# SPC1068 register map
File version: 20180100_70611510
CPU: CM3 r2p1, little endian, MPU, no FPU, 4 interrupt priority bits
Registers are 32-bit, read-write, reset 0x0 unless marked. A register's access mark holds for its fields unless they carry their own. Offsets are from the block's base; [hi:lo] are bit positions.

## PINMUX — Split from GLOBAL
Base 0x4000B000
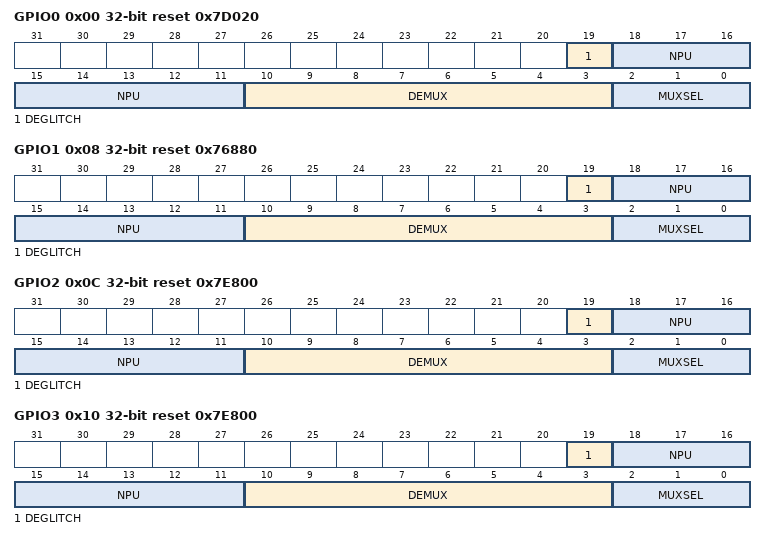
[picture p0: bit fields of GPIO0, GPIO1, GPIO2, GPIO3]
0x00 GPIO0 reset 0x7D020 — GPIO0 Pin Configuration Register
  [19] DEGLITCH — Input de-glitch filtering
    0=DISABLE (Disable de-glitch); 1=ENABLE (Enable de-glitch)
  [18:11] NPU — Disable internal pull-up for each channel
  [10:3] DEMUX — Default value for each demuxed input channel
  [2:0] MUXSEL — Channel select
    0=GPIO0; 1=UART_TXD; 2=I2C_SCL; 7=ECAPO (ECAP output)
0x08 GPIO1 reset 0x76880 — GPIO1 Pin Configuration Register
  [19] DEGLITCH — Input de-glitch filtering
    0=DISABLE (Disable de-glitch); 1=ENABLE (Enable de-glitch)
  [18:11] NPU — Disable internal pull-up for each channel
  [10:3] DEMUX — Default value for each demuxed input channel
  [2:0] MUXSEL — Channel select
    0=ADC0; 1=GPIO1; 2=PWMSYNCI; 3=PWMSYNCO; 4=I2C_SDA; 7=ECAPO (ECAP output)
0x0C GPIO2 reset 0x7E800 — GPIO2 Pin Configuration Register
  [19] DEGLITCH — Input de-glitch filtering
    0=DISABLE (Disable de-glitch); 1=ENABLE (Enable de-glitch)
  [18:11] NPU — Disable internal pull-up for each channel
  [10:3] DEMUX — Default value for each demuxed input channel
  [2:0] MUXSEL — Channel select
    0=ADC1; 1=GPIO2; 2=PWM5B; 7=ECAPO (ECAP output)
0x10 GPIO3 reset 0x7E800 — GPIO3 Pin Configuration Register
  [19] DEGLITCH — Input de-glitch filtering
    0=DISABLE (Disable de-glitch); 1=ENABLE (Enable de-glitch)
  [18:11] NPU — Disable internal pull-up for each channel
  [10:3] DEMUX — Default value for each demuxed input channel
  [2:0] MUXSEL — Channel select
    0=ADC2; 1=GPIO3; 2=PWM5A; 7=ECAPO (ECAP output)
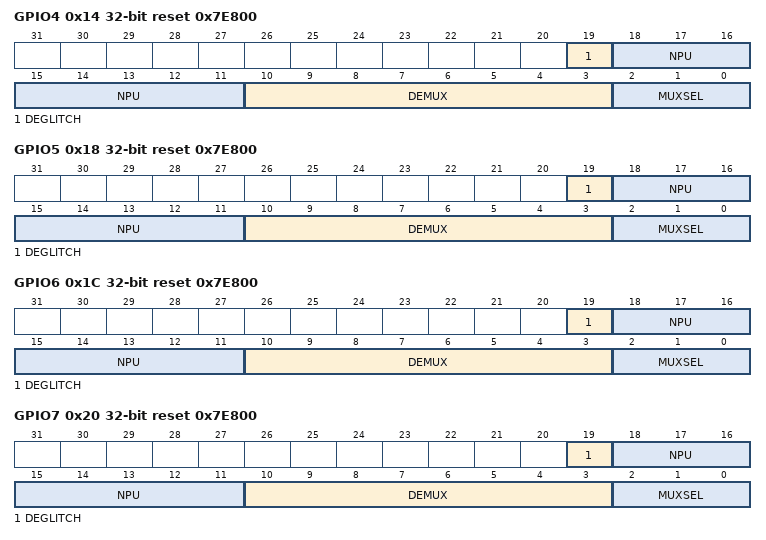
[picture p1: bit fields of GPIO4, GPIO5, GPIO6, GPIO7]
0x14 GPIO4 reset 0x7E800 — GPIO4 Pin Configuration Register
  [19] DEGLITCH — Input de-glitch filtering
    0=DISABLE (Disable de-glitch); 1=ENABLE (Enable de-glitch)
  [18:11] NPU — Disable internal pull-up for each channel
  [10:3] DEMUX — Default value for each demuxed input channel
  [2:0] MUXSEL — Channel select
    0=ADC3; 1=GPIO4; 2=PWM6B; 7=ECAPO (ECAP output)
0x18 GPIO5 reset 0x7E800 — GPIO5 Pin Configuration Register
  [19] DEGLITCH — Input de-glitch filtering
    0=DISABLE (Disable de-glitch); 1=ENABLE (Enable de-glitch)
  [18:11] NPU — Disable internal pull-up for each channel
  [10:3] DEMUX — Default value for each demuxed input channel
  [2:0] MUXSEL — Channel select
    0=ADC4; 1=GPIO5; 2=PWM6A; 7=ECAPO (ECAP output)
0x1C GPIO6 reset 0x7E800 — GPIO6 Pin Configuration Register
  [19] DEGLITCH — Input de-glitch filtering
    0=DISABLE (Disable de-glitch); 1=ENABLE (Enable de-glitch)
  [18:11] NPU — Disable internal pull-up for each channel
  [10:3] DEMUX — Default value for each demuxed input channel
  [2:0] MUXSEL — Channel select
    0=ADC5; 1=GPIO6; 2=PWM4B; 7=ECAPO (ECAP output)
0x20 GPIO7 reset 0x7E800 — GPIO7 Pin Configuration Register
  [19] DEGLITCH — Input de-glitch filtering
    0=DISABLE (Disable de-glitch); 1=ENABLE (Enable de-glitch)
  [18:11] NPU — Disable internal pull-up for each channel
  [10:3] DEMUX — Default value for each demuxed input channel
  [2:0] MUXSEL — Channel select
    0=ADC6; 1=GPIO7; 2=PWM4A; 7=ECAPO (ECAP output)
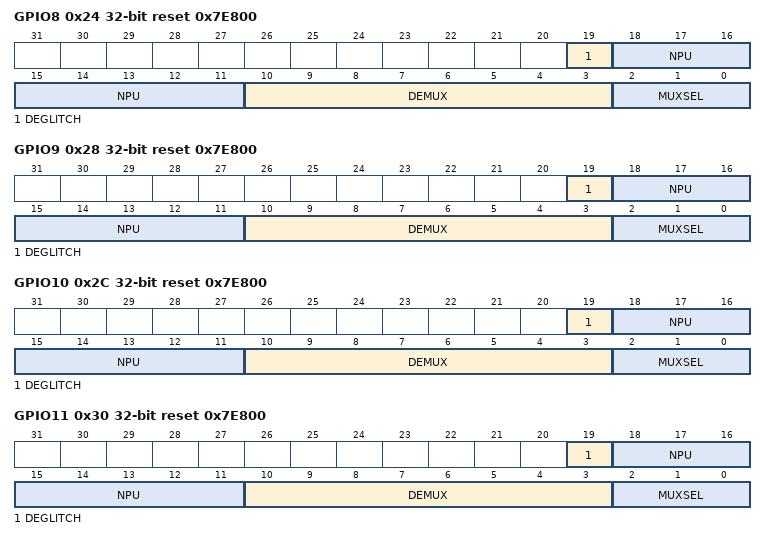
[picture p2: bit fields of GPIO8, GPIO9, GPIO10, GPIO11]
0x24 GPIO8 reset 0x7E800 — GPIO8 Pin Configuration Register
  [19] DEGLITCH — Input de-glitch filtering
    0=DISABLE (Disable de-glitch); 1=ENABLE (Enable de-glitch)
  [18:11] NPU — Disable internal pull-up for each channel
  [10:3] DEMUX — Default value for each demuxed input channel
  [2:0] MUXSEL — Channel select
    0=ADC7; 1=GPIO8; 2=PWM4A; 3=COMP0HOUT; 7=ECAPO (ECAP output)
0x28 GPIO9 reset 0x7E800 — GPIO9 Pin Configuration Register
  [19] DEGLITCH — Input de-glitch filtering
    0=DISABLE (Disable de-glitch); 1=ENABLE (Enable de-glitch)
  [18:11] NPU — Disable internal pull-up for each channel
  [10:3] DEMUX — Default value for each demuxed input channel
  [2:0] MUXSEL — Channel select
    0=ADC8; 1=GPIO9; 2=PWM4B; 3=COMP1HOUT; 7=ECAPO (ECAP output)
0x2C GPIO10 reset 0x7E800 — GPIO10 Pin Configuration Register
  [19] DEGLITCH — Input de-glitch filtering
    0=DISABLE (Disable de-glitch); 1=ENABLE (Enable de-glitch)
  [18:11] NPU — Disable internal pull-up for each channel
  [10:3] DEMUX — Default value for each demuxed input channel
  [2:0] MUXSEL — Channel select
    0=ADC9; 1=GPIO10; 2=PWM6A; 3=COMP2HOUT; 7=ECAPO (ECAP output)
0x30 GPIO11 reset 0x7E800 — GPIO11 Pin Configuration Register
  [19] DEGLITCH — Input de-glitch filtering
    0=DISABLE (Disable de-glitch); 1=ENABLE (Enable de-glitch)
  [18:11] NPU — Disable internal pull-up for each channel
  [10:3] DEMUX — Default value for each demuxed input channel
  [2:0] MUXSEL — Channel select
    0=ADC10; 1=GPIO11; 2=PWM6B; 3=COMP0LOUT; 7=ECAPO (ECAP output)
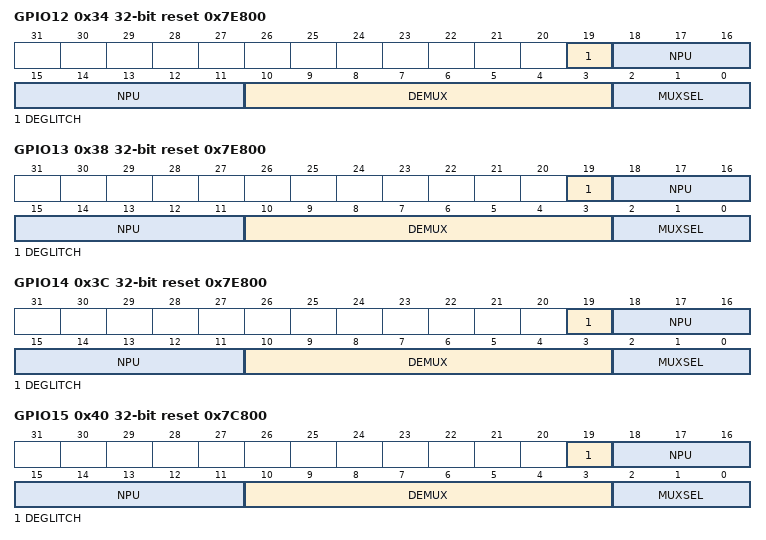
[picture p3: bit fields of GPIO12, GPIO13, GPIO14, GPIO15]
0x34 GPIO12 reset 0x7E800 — GPIO12 Pin Configuration Register
  [19] DEGLITCH — Input de-glitch filtering
    0=DISABLE (Disable de-glitch); 1=ENABLE (Enable de-glitch)
  [18:11] NPU — Disable internal pull-up for each channel
  [10:3] DEMUX — Default value for each demuxed input channel
  [2:0] MUXSEL — Channel select
    0=ADC11; 1=GPIO12; 2=PWM5A; 3=COMP1LOUT; 7=ECAPO (ECAP output)
0x38 GPIO13 reset 0x7E800 — GPIO13 Pin Configuration Register
  [19] DEGLITCH — Input de-glitch filtering
    0=DISABLE (Disable de-glitch); 1=ENABLE (Enable de-glitch)
  [18:11] NPU — Disable internal pull-up for each channel
  [10:3] DEMUX — Default value for each demuxed input channel
  [2:0] MUXSEL — Channel select
    0=ADC12; 1=GPIO13; 2=PWM5B; 3=COMP2LOUT; 7=ECAPO (ECAP output)
0x3C GPIO14 reset 0x7E800 — GPIO14 Pin Configuration Register
  [19] DEGLITCH — Input de-glitch filtering
    0=DISABLE (Disable de-glitch); 1=ENABLE (Enable de-glitch)
  [18:11] NPU — Disable internal pull-up for each channel
  [10:3] DEMUX — Default value for each demuxed input channel
  [2:0] MUXSEL — Channel select
    0=ADC13; 1=GPIO14; 7=ECAPO (ECAP output)
0x40 GPIO15 reset 0x7C800 — GPIO15 Pin Configuration Register
  [19] DEGLITCH — Input de-glitch filtering
    0=DISABLE (Disable de-glitch); 1=ENABLE (Enable de-glitch)
  [18:11] NPU — Disable internal pull-up for each channel
  [10:3] DEMUX — Default value for each demuxed input channel
  [2:0] MUXSEL — Channel select
    0=ADC14; 1=GPIO15; 2=TDI; 7=ECAPO (ECAP output)
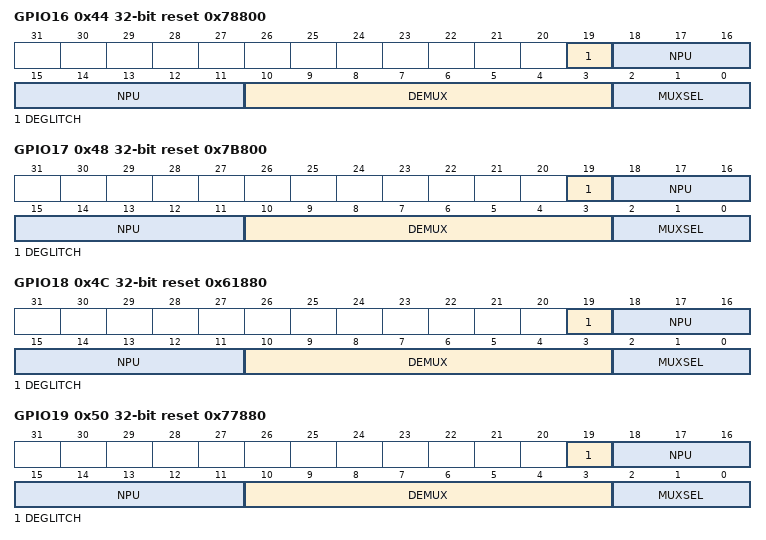
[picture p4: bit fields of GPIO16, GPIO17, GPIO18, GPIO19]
0x44 GPIO16 reset 0x78800 — GPIO16 Pin Configuration Register
  [19] DEGLITCH — Input de-glitch filtering
    0=DISABLE (Disable de-glitch); 1=ENABLE (Enable de-glitch)
  [18:11] NPU — Disable internal pull-up for each channel
  [10:3] DEMUX — Default value for each demuxed input channel
  [2:0] MUXSEL — Channel select
    0=ADC15; 1=GPIO16; 2=TMS_SWD; 7=ECAPO (ECAP output)
0x48 GPIO17 reset 0x7B800 — GPIO17 Pin Configuration Register
  [19] DEGLITCH — Input de-glitch filtering
    0=DISABLE (Disable de-glitch); 1=ENABLE (Enable de-glitch)
  [18:11] NPU — Disable internal pull-up for each channel
  [10:3] DEMUX — Default value for each demuxed input channel
  [2:0] MUXSEL — Channel select
    0=GPIO17; 2=TDO; 3=TMS_SWD; 5=SPI_FRM; 6=PWM6B; 7=ECAPO (ECAP output)
0x4C GPIO18 reset 0x61880 — GPIO18 Pin Configuration Register
  [19] DEGLITCH — Input de-glitch filtering
    0=DISABLE (Disable de-glitch); 1=ENABLE (Enable de-glitch)
  [18:11] NPU — Disable internal pull-up for each channel
  [10:3] DEMUX — Default value for each demuxed input channel
  [2:0] MUXSEL — Channel select
    0=GPIO18; 1=SPIMO; 2=TCK_SWCK; 4=I2C_SDA; 5=SPIMI; 6=PWM6A; 7=ECAPO (ECAP output)
0x50 GPIO19 reset 0x77880 — GPIO19 Pin Configuration Register
  [19] DEGLITCH — Input de-glitch filtering
    0=DISABLE (Disable de-glitch); 1=ENABLE (Enable de-glitch)
  [18:11] NPU — Disable internal pull-up for each channel
  [10:3] DEMUX — Default value for each demuxed input channel
  [2:0] MUXSEL — Channel select
    0=GPIO19; 1=SPICLK; 2=UART_TXD; 3=CLK_TEST; 4=I2C_SCL; 5=SPICLK; 6=PWM5B; 7=ECAPO (ECAP output)
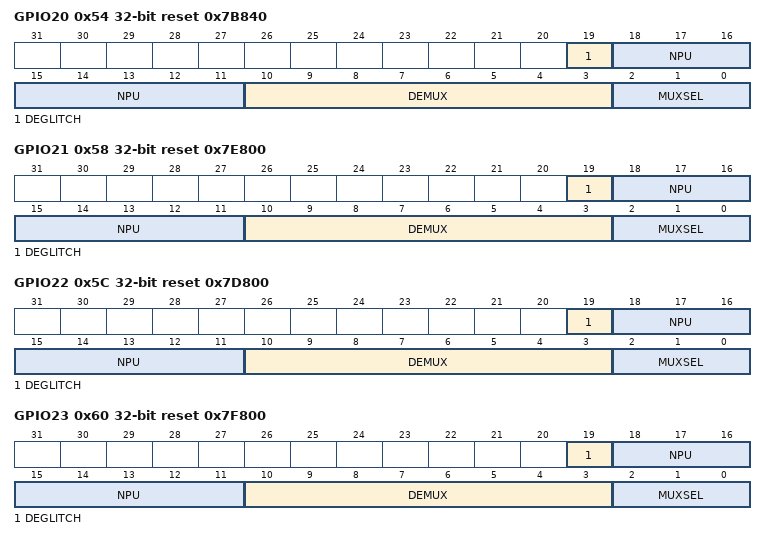
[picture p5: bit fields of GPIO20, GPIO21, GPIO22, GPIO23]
0x54 GPIO20 reset 0x7B840 — GPIO20 Pin Configuration Register
  [19] DEGLITCH — Input de-glitch filtering
    0=DISABLE (Disable de-glitch); 1=ENABLE (Enable de-glitch)
  [18:11] NPU — Disable internal pull-up for each channel
  [10:3] DEMUX — Default value for each demuxed input channel
  [2:0] MUXSEL — Channel select
    0=GPIO20; 2=SPI_FRM; 3=UART_RXD; 6=PWM5A; 7=ECAPO (ECAP output)
0x58 GPIO21 reset 0x7E800 — GPIO21 Pin Configuration Register
  [19] DEGLITCH — Input de-glitch filtering
    0=DISABLE (Disable de-glitch); 1=ENABLE (Enable de-glitch)
  [18:11] NPU — Disable internal pull-up for each channel
  [10:3] DEMUX — Default value for each demuxed input channel
  [2:0] MUXSEL — Channel select
    0=GPIO21; 1=SPIMI; 2=SPISO; 6=PWM4B; 7=ECAPO (ECAP output)
0x5C GPIO22 reset 0x7D800 — GPIO22 Pin Configuration Register
  [19] DEGLITCH — Input de-glitch filtering
    0=DISABLE (Disable de-glitch); 1=ENABLE (Enable de-glitch)
  [18:11] NPU — Disable internal pull-up for each channel
  [10:3] DEMUX — Default value for each demuxed input channel
  [2:0] MUXSEL — Channel select
    0=GPIO22; 1=SPIMO; 2=SPISI; 6=PWM4A; 7=ECAPO (ECAP output)
0x60 GPIO23 reset 0x7F800 — GPIO23 Pin Configuration Register
  [19] DEGLITCH — Input de-glitch filtering
    0=DISABLE (Disable de-glitch); 1=ENABLE (Enable de-glitch)
  [18:11] NPU — Disable internal pull-up for each channel
  [10:3] DEMUX — Default value for each demuxed input channel
  [2:0] MUXSEL — Channel select
    0=GPIO23; 1=PWM0B; 2=COMP0LOUT; 7=ECAPO (ECAP output)
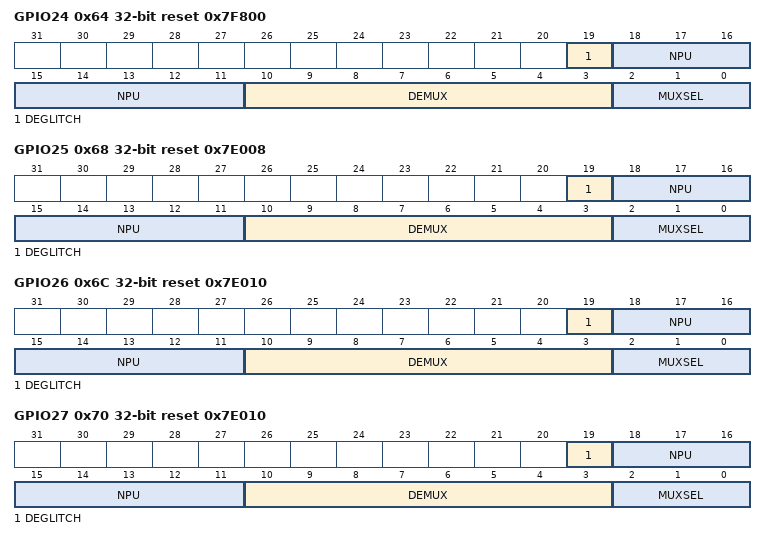
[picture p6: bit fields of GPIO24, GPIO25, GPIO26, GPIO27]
0x64 GPIO24 reset 0x7F800 — GPIO24 Pin Configuration Register
  [19] DEGLITCH — Input de-glitch filtering
    0=DISABLE (Disable de-glitch); 1=ENABLE (Enable de-glitch)
  [18:11] NPU — Disable internal pull-up for each channel
  [10:3] DEMUX — Default value for each demuxed input channel
  [2:0] MUXSEL — Channel select
    0=GPIO24; 1=PWM0A; 2=ATEST; 7=ECAPO (ECAP output)
0x68 GPIO25 reset 0x7E008 — GPIO25 Pin Configuration Register
  [19] DEGLITCH — Input de-glitch filtering
    0=DISABLE (Disable de-glitch); 1=ENABLE (Enable de-glitch)
  [18:11] NPU — Disable internal pull-up for each channel
  [10:3] DEMUX — Default value for each demuxed input channel
  [2:0] MUXSEL — Channel select
    0=TEST; 1=GPIO25; 7=ECAPO (ECAP output)
0x6C GPIO26 reset 0x7E010 — GPIO26 Pin Configuration Register
  [19] DEGLITCH — Input de-glitch filtering
    0=DISABLE (Disable de-glitch); 1=ENABLE (Enable de-glitch)
  [18:11] NPU — Disable internal pull-up for each channel
  [10:3] DEMUX — Default value for each demuxed input channel
  [2:0] MUXSEL — Channel select
    0=GPIO26; 1=I2C_SDA; 2=PWMSYNCI; 3=ADCSOCAO; 7=ECAPO (ECAP output)
0x70 GPIO27 reset 0x7E010 — GPIO27 Pin Configuration Register
  [19] DEGLITCH — Input de-glitch filtering
    0=DISABLE (Disable de-glitch); 1=ENABLE (Enable de-glitch)
  [18:11] NPU — Disable internal pull-up for each channel
  [10:3] DEMUX — Default value for each demuxed input channel
  [2:0] MUXSEL — Channel select
    0=GPIO27; 1=I2C_SCL; 2=PWMSYNCO; 3=ADCSOCBO; 7=ECAPO (ECAP output)
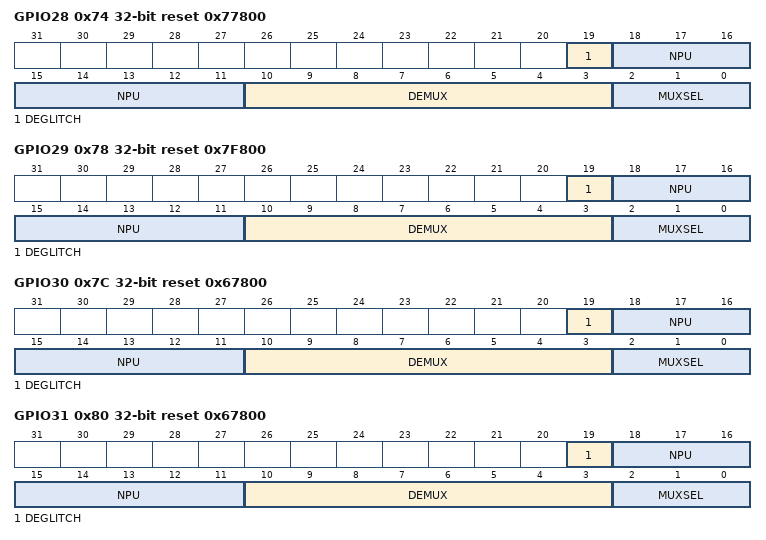
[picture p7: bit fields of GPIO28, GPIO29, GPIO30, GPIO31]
0x74 GPIO28 reset 0x77800 — GPIO28 Pin Configuration Register
  [19] DEGLITCH — Input de-glitch filtering
    0=DISABLE (Disable de-glitch); 1=ENABLE (Enable de-glitch)
  [18:11] NPU — Disable internal pull-up for each channel
  [10:3] DEMUX — Default value for each demuxed input channel
  [2:0] MUXSEL — Channel select
    0=GPIO28; 1=PWM1A; 4=TDI; 7=ECAPO (ECAP output)
0x78 GPIO29 reset 0x7F800 — GPIO29 Pin Configuration Register
  [19] DEGLITCH — Input de-glitch filtering
    0=DISABLE (Disable de-glitch); 1=ENABLE (Enable de-glitch)
  [18:11] NPU — Disable internal pull-up for each channel
  [10:3] DEMUX — Default value for each demuxed input channel
  [2:0] MUXSEL — Channel select
    0=GPIO29; 1=PWM1B; 2=COMP0HOUT; 4=TDO; 7=ECAPO
0x7C GPIO30 reset 0x67800 — GPIO30 Pin Configuration Register
  [19] DEGLITCH — Input de-glitch filtering
    0=DISABLE (Disable de-glitch); 1=ENABLE (Enable de-glitch)
  [18:11] NPU — Disable internal pull-up for each channel
  [10:3] DEMUX — Default value for each demuxed input channel
  [2:0] MUXSEL — Channel select
    0=GPIO30; 1=PWM2A; 4=TMS_SWD; 5=TMS_SWD; 7=ECAPO (ECAP output)
0x80 GPIO31 reset 0x67800 — GPIO31 Pin Configuration Register
  [19] DEGLITCH — Input de-glitch filtering
    0=DISABLE (Disable de-glitch); 1=ENABLE (Enable de-glitch)
  [18:11] NPU — Disable internal pull-up for each channel
  [10:3] DEMUX — Default value for each demuxed input channel
  [2:0] MUXSEL — Channel select
    0=GPIO31; 1=PWM2B; 4=TCK_SWCK; 7=ECAPO (ECAP output)
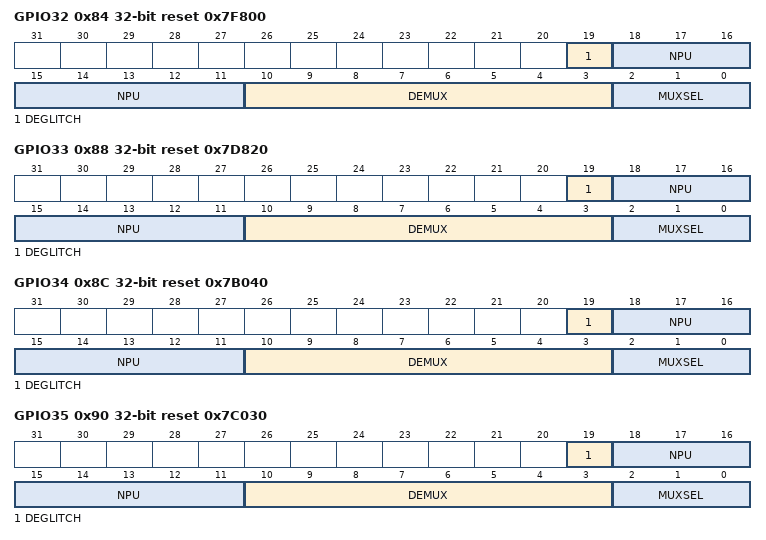
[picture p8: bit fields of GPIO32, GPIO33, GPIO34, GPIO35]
0x84 GPIO32 reset 0x7F800 — GPIO32 Pin Configuration Register
  [19] DEGLITCH — Input de-glitch filtering
    0=DISABLE (Disable de-glitch); 1=ENABLE (Enable de-glitch)
  [18:11] NPU — Disable internal pull-up for each channel
  [10:3] DEMUX — Default value for each demuxed input channel
  [2:0] MUXSEL — Channel select
    0=GPIO32; 1=PWM3A; 2=PWMSYNCI; 3=PWMSYNCO; 4=SPICLK; 7=ECAPO (ECAP output)
0x88 GPIO33 reset 0x7D820 — GPIO33 Pin Configuration Register
  [19] DEGLITCH — Input de-glitch filtering
    0=DISABLE (Disable de-glitch); 1=ENABLE (Enable de-glitch)
  [18:11] NPU — Disable internal pull-up for each channel
  [10:3] DEMUX — Default value for each demuxed input channel
  [2:0] MUXSEL — Channel select
    0=GPIO33; 1=PWM3B; 2=UART_RXD; 4=SPI_FRM; 7=ECAPO (ECAP output)
0x8C GPIO34 reset 0x7B040 — GPIO34 Pin Configuration Register
  [19] DEGLITCH — Input de-glitch filtering
    0=DISABLE (Disable de-glitch); 1=ENABLE (Enable de-glitch)
  [18:11] NPU — Disable internal pull-up for each channel
  [10:3] DEMUX — Default value for each demuxed input channel
  [2:0] MUXSEL — Channel select
    0=GPIO34; 1=UART_TXD; 3=UART_RXD; 7=ECAPO (ECAP output)
0x90 GPIO35 reset 0x7C030 — GPIO35 Pin Configuration Register
  [19] DEGLITCH — Input de-glitch filtering
    0=DISABLE (Disable de-glitch); 1=ENABLE (Enable de-glitch)
  [18:11] NPU — Disable internal pull-up for each channel
  [10:3] DEMUX — Default value for each demuxed input channel
  [2:0] MUXSEL — Channel select
    0=GPIO35; 1=UART_RXD; 2=I2C_SDA; 3=UART_TXD; 7=ECAPO (ECAP output)
